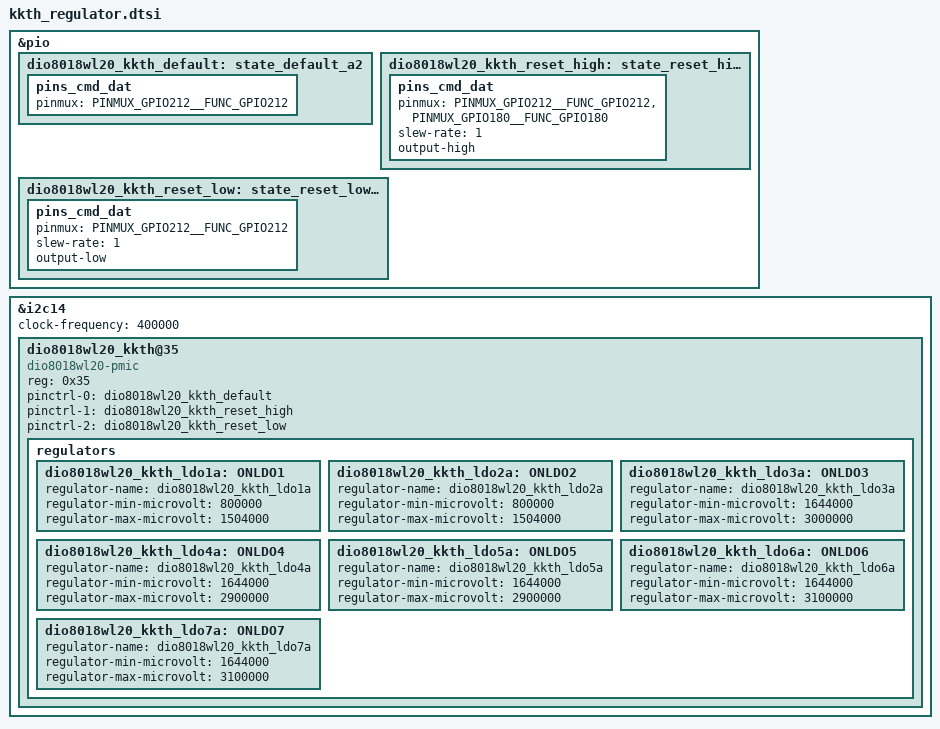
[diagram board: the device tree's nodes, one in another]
// SPDX-License-Identifier: GPL-2.0
/*
 * Copyright (C) 2021 MediaTek Inc.
 */

&pio {
	dio8018wl20_kkth_default: state_default_a2 {
		pins_cmd_dat {
			pinmux = <PINMUX_GPIO212__FUNC_GPIO212>;
		};
	};
	// GPIO90 pull up to enable dvdd supply
	dio8018wl20_kkth_reset_high: state_reset_high_a2 {
		pins_cmd_dat {
			pinmux = <PINMUX_GPIO212__FUNC_GPIO212>,
			<PINMUX_GPIO180__FUNC_GPIO180>;
			slew-rate = <1>;
			output-high;
		};
	};
	dio8018wl20_kkth_reset_low: state_reset_low_a2 {
		pins_cmd_dat {
			pinmux = <PINMUX_GPIO212__FUNC_GPIO212>;
			slew-rate = <1>;
			output-low;
		};
	};
};

&i2c14 {
	clock-frequency = <400000>;
	dio8018wl20_kkth@35 {
		compatible = "dio8018wl20-pmic";
		reg = <0x35>;
		pinctrl-names = "default", "reset_high", "reset_low";
		pinctrl-0 = <&dio8018wl20_kkth_default>;
		pinctrl-1 = <&dio8018wl20_kkth_reset_high>;
		pinctrl-2 = <&dio8018wl20_kkth_reset_low>;
		regulators {
			dio8018wl20_kkth_ldo1a:ONLDO1 {
				regulator-name = "dio8018wl20_kkth_ldo1a";
				regulator-min-microvolt = <800000>;
				regulator-max-microvolt = <1504000>;
			};
			dio8018wl20_kkth_ldo2a:ONLDO2 {
				regulator-name = "dio8018wl20_kkth_ldo2a";
				regulator-min-microvolt = <800000>;
				regulator-max-microvolt = <1504000>;
			};
			//avdd 2.8
			dio8018wl20_kkth_ldo3a:ONLDO3 {
				regulator-name = "dio8018wl20_kkth_ldo3a";
				regulator-min-microvolt = <1644000>;
				regulator-max-microvolt = <3000000>;
			};
			dio8018wl20_kkth_ldo4a:ONLDO4 {
				regulator-name = "dio8018wl20_kkth_ldo4a";
				regulator-min-microvolt = <1644000>;
				regulator-max-microvolt = <2900000>;
			};
			//
			dio8018wl20_kkth_ldo5a:ONLDO5 {
				regulator-name = "dio8018wl20_kkth_ldo5a";
				regulator-min-microvolt = <1644000>;
				regulator-max-microvolt = <2900000>;
			};
			dio8018wl20_kkth_ldo6a:ONLDO6 {
				regulator-name = "dio8018wl20_kkth_ldo6a";
				regulator-min-microvolt = <1644000>;
				regulator-max-microvolt = <3100000>;
			};
			dio8018wl20_kkth_ldo7a:ONLDO7 {
				regulator-name = "dio8018wl20_kkth_ldo7a";
				regulator-min-microvolt = <1644000>;
				regulator-max-microvolt = <3100000>;
			};
		};
	};
};



